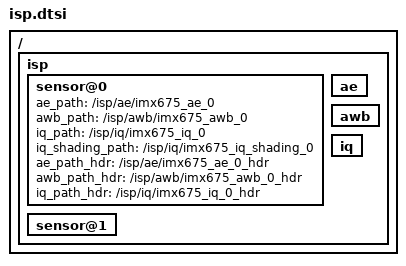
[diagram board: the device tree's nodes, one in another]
/ {
	isp {
		sensor@0 {
			ae_path                 = "/isp/ae/imx675_ae_0";
			awb_path                = "/isp/awb/imx675_awb_0";
			iq_path                 = "/isp/iq/imx675_iq_0";
			iq_shading_path			= "/isp/iq/imx675_iq_shading_0";
			/*HDR PATH                                      */
			ae_path_hdr             = "/isp/ae/imx675_ae_0_hdr";
			awb_path_hdr            = "/isp/awb/imx675_awb_0_hdr";
			iq_path_hdr             = "/isp/iq/imx675_iq_0_hdr";
		};
		sensor@1 {
		};
		/* label for ae, awb, iq table */
		ae: ae {
		};
		awb: awb {
		};
		iq: iq {
		};
	};
};

/* Note: put include files in the tail since label should be declared first. */
#include "imx675_ae_0.dtsi"
#include "imx675_awb_0.dtsi"
#include "imx675_iq_0.dtsi"
#include "imx675_iq_shading_0.dtsi"
#include "imx675_ae_0_hdr.dtsi"
#include "imx675_awb_0_hdr.dtsi"
#include "imx675_iq_0_hdr.dtsi"

